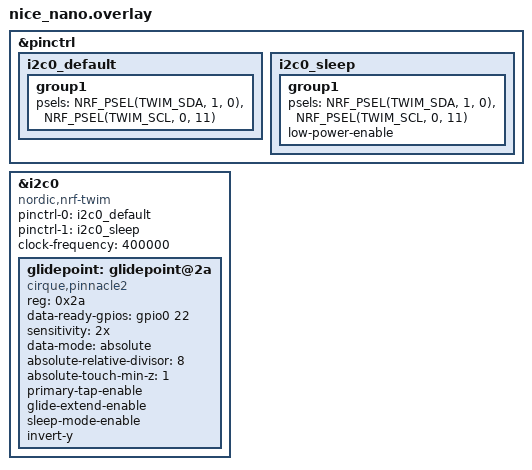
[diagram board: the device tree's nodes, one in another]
/**
 * Generated by Shield Wizard for ZMK
 * Applies to part "unibody" with controller "nice_nano_v2"
 */

// pin control for i2c0
// - SDA on D6
// - SCL on D7
&pinctrl {
    /* configuration for i2c0 device, default state */
    i2c0_default: i2c0_default {
        group1 {
            psels = <NRF_PSEL(TWIM_SDA, 1, 0)>,
                    <NRF_PSEL(TWIM_SCL, 0, 11)>;
        };
    };
    /* configuration for i2c0 device, sleep state */
    i2c0_sleep: i2c0_sleep {
        group1 {
            psels = <NRF_PSEL(TWIM_SDA, 1, 0)>,
                    <NRF_PSEL(TWIM_SCL, 0, 11)>;
            low-power-enable;
        };
    };
};
&i2c0 {
    compatible = "nordic,nrf-twim";
    status = "okay";

    pinctrl-0 = <&i2c0_default>;
    pinctrl-1 = <&i2c0_sleep>;
    pinctrl-names = "default", "sleep";
    clock-frequency = <400000>;

    glidepoint: glidepoint@2a {
        compatible = "cirque,pinnacle2";
        reg = <0x2a>;
        status = "okay";
        data-ready-gpios = <&gpio0 22 GPIO_ACTIVE_HIGH>;
        sensitivity = "2x";
        data-mode = "absolute"; /* or "relative" for the ASIC's stock behavior */
        absolute-relative-divisor = <8>;
        absolute-touch-min-z = <1>;
        primary-tap-enable;
        glide-extend-enable; /* Used only when switching to relative mode. */
        sleep-mode-enable;
        invert-y;
    };
};
